# HC32M458 register map
File version: 1.0
CPU: CM4 r0p1, little endian, MPU, FPU, 4 interrupt priority bits
Registers are 16-bit, read-write, reset 0x0 unless marked. A register's access mark holds for its fields unless they carry their own. Offsets are from the block's base; lines under a group give offsets from that group; [hi:lo] are bit positions; {n}, {i} and the like mark numbered series; 'fields as' and 'values as' point back to an identical list; <NAME> marks a mode.

## Memory map
0x00080000 ICG size 0x14
0x01001C50 EFM2 size 0x10
0x40010400 EFM size 0x289
0x40010800 AOS size 0x30
0x40017C00 EMB0 size 0x20 — desc EMB
0x40017C20 EMB1 size 0x20 — desc EMB
0x40017C40 EMB2 size 0x20 — desc EMB
0x40017C60 EMB3 size 0x20 — desc EMB
0x4001C000 SPI1 size 0x1C — desc SPI
0x4001C400 SPI2 size 0x1C — desc SPI
0x4001CC00 USART1 size 0x20 — desc USART
0x4001D000 USART2 size 0x20 — desc USART
0x40020C00 USART3 size 0x20 — desc USART
0x40021000 USART4 size 0x20 — desc USART
0x40024000 TMR01 size 0x18 — desc TMR0
0x40024400 TMR02 size 0x18 — desc TMR0
0x40026000 TMRA5 size 0x1AA — desc TMRA
0x40038000 TMR41 size 0x116
0x40038400 TMR42 size 0x116
0x40038800 CMP1 size 0x20 — desc CMP
0x40038900 CMP2 size 0x20 — desc CMP
0x4003A000 TMRA1 size 0x1AA — desc TMRA
0x4003A400 TMRA2 size 0x1AA — desc TMRA
0x4003A800 TMRA3 size 0x1AA — desc TMRA
0x4003AC00 TMRA4 size 0x1AA — desc TMRA
0x4003B400 I2C size 0x3C
0x40040000 ADC1 size 0xC4
0x40040400 ADC2 size 0xB1
0x40042000 TRNG size 0x14
0x40048400 FCM size 0x24
0x40049000 WDT size 0xC
0x40049400 SWDT size 0xC
0x40050000 DFM size 0x40
0x40050400 CRC size 0x100
0x40050800 SRAMC size 0x34
0x40051000 INTC size 0x6C
0x40053000 DMA size 0xB8
0x40053800 GPIO size 0x7CC
0x40054000 CMU size 0x49
0x40054400 PWC size 0x54
0x40054500 RMU size 0x20
0x40054800 MAU size 0x2C
0x40055400 PERIC size 0x20
0xE0042000 DBGC size 0x40

## Interrupts
11 SWDT — SWDT underflow or update error interrupt
12 LVD1 (PWC) — Low voltage detect unit 1 interrupt
13 LVD2 (PWC) — Low voltage detect unit 2 interrupt

## ADC1
Base 0x40040000
0x00 STR 8-bit
  [0] STRT
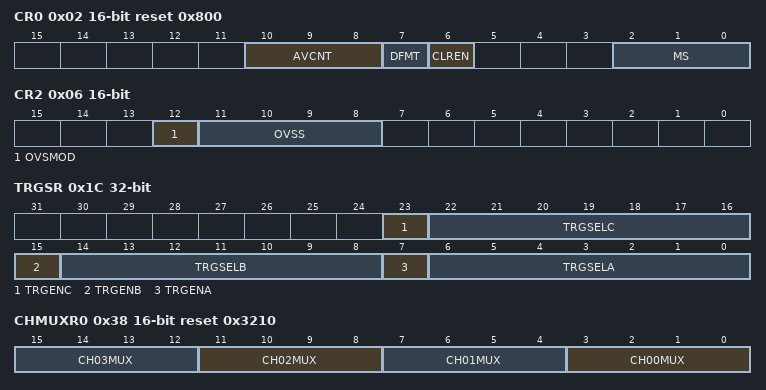
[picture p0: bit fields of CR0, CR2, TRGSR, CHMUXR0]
0x02 CR0 reset 0x800
  [10:8] AVCNT, [7] DFMT, [6] CLREN, [2:0] MS
0x04 CR1 reset 0xC0
  [2] RSCHSEL
0x06 CR2
  [12] OVSMOD, [11:8] OVSS
0x0C CHSELRA 32-bit
  [16:0] CHSELA
0x10 CHSELRB 32-bit
  [16:0] CHSELB
0x14 AVCHSELR 32-bit
  [16:0] AVCHSEL
0x18 ADC_EXCHSELR 8-bit
  [1:0] EXCHSEL
0x1C TRGSR 32-bit
  [23] TRGENC, [22:16] TRGSELC, [15] TRGENB, [14:8] TRGSELB, [7] TRGENA, [6:0] TRGSELA
{0x20+i} SSTR{i} 8-bit reset 0x4 (i=0..15)
0x38 CHMUXR0 reset 0x3210
  [4n+3:4n] CH{n:02}MUX (n=0..3)
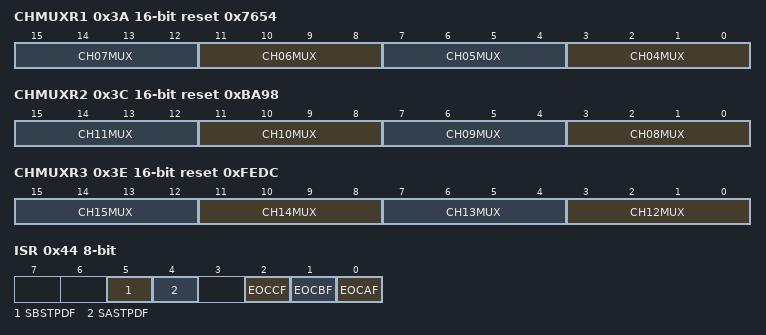
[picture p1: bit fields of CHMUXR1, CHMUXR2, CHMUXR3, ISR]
0x3A CHMUXR1 reset 0x7654
  [4n-13:4n-16] CH{n:02}MUX (n=4..7)
0x3C CHMUXR2 reset 0xBA98
  [4n-29:4n-32] CH{n:02}MUX (n=8..11)
0x3E CHMUXR3 reset 0xFEDC
  [4n-45:4n-48] CH{n}MUX (n=12..15)
0x40 CHSELRC 32-bit
  [16:0] CHSELC
0x44 ISR 8-bit ro
  [5] SBSTPDF, [4] SASTPDF, [2] EOCCF, [1] EOCBF, [0] EOCAF
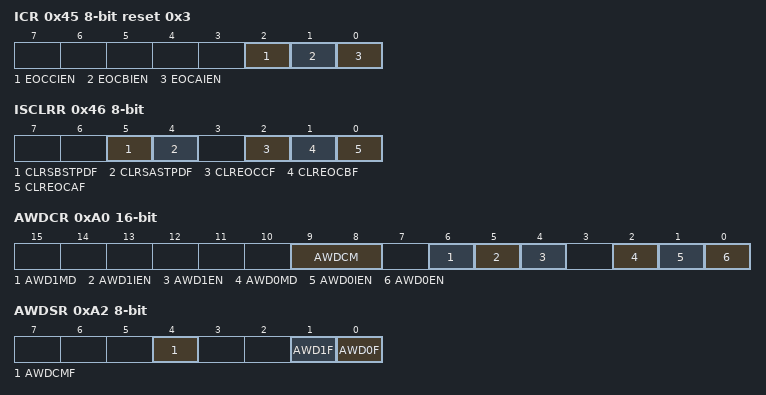
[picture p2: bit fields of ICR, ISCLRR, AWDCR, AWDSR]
0x45 ICR 8-bit reset 0x3
  [2] EOCCIEN, [1] EOCBIEN, [0] EOCAIEN
0x46 ISCLRR 8-bit wo
  [5] CLRSBSTPDF, [4] CLRSASTPDF, [2] CLREOCCF, [1] CLREOCBF, [0] CLREOCAF
{0x50+2i} DR{i} ro (i=0..15)
0xA0 AWDCR
  [9:8] AWDCM, [6] AWD1MD, [5] AWD1IEN, [4] AWD1EN, [2] AWD0MD, [1] AWD0IEN, [0] AWD0EN
0xA2 AWDSR 8-bit ro
  [4] AWDCMF, [1] AWD1F, [0] AWD0F
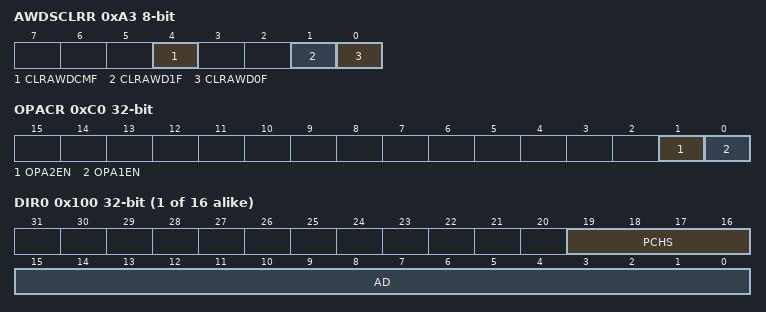
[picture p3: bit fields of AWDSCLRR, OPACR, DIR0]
0xA3 AWDSCLRR 8-bit wo
  [4] CLRAWDCMF, [1] CLRAWD1F, [0] CLRAWD0F
0xA4 AWD0DR0
0xA6 AWD0DR1 reset 0xFFFF
0xA8 AWD0CHSR 8-bit
  [4:0] AWDCH
0xAC AWD1DR0
0xAE AWD1DR1 reset 0xFFFF
0xB0 AWD1CHSR 8-bit
  [4:0] AWDCH
0xC0 OPACR 32-bit
  [1] OPA2EN, [0] OPA1EN
{0x100+4i} DIR{i} 32-bit ro (i=0..15)
  [19:16] PCHS, [15:0] AD

## ADC2
Base 0x40040400
Registers as ADC1, without SSTR{n} (n=9..15), DR{n} (n=9..15), OPACR, DIR{n} (n=9..15); these are added or differ:
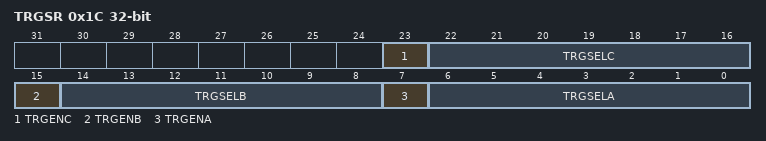
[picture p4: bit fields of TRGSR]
0x1C TRGSR 32-bit (reset mask 0x878787)
  [23] TRGENC, [22:16] TRGSELC, [15] TRGENB, [14:8] TRGSELB, [7] TRGENA, [6:0] TRGSELA

## AOS
Base 0x40010800
0x00 INTSFTTRG 32-bit wo
  [0] STRG
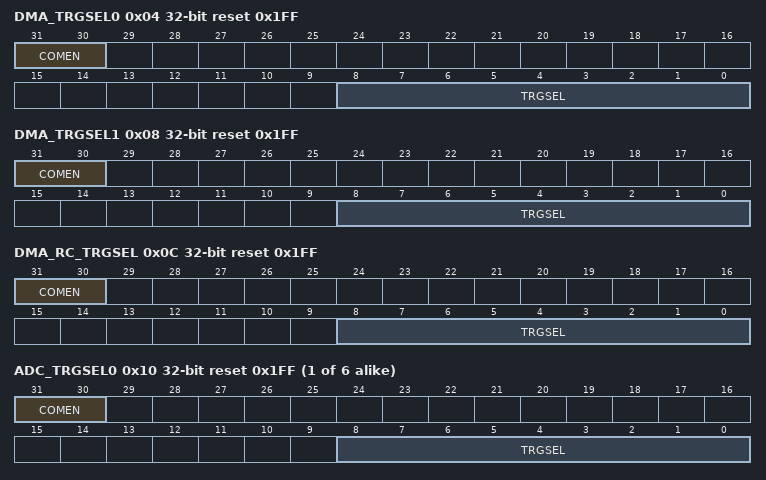
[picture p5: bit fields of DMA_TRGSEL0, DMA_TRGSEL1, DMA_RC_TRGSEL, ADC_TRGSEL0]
0x04 DMA_TRGSEL0 32-bit reset 0x1FF
  [31:30] COMEN, [8:0] TRGSEL
0x08 DMA_TRGSEL1 32-bit reset 0x1FF
  [31:30] COMEN, [8:0] TRGSEL
0x0C DMA_RC_TRGSEL 32-bit reset 0x1FF
  [31:30] COMEN, [8:0] TRGSEL
{0x10+4i} ADC_TRGSEL{i} 32-bit reset 0x1FF (i=0..5)
  [31:30] COMEN, [8:0] TRGSEL
0x28 COMTRGSEL1 32-bit reset 0x1FF
  [8:0] TRGSEL
0x2C COMTRGSEL2 32-bit reset 0x1FF
  [8:0] TRGSEL
